# USB0_VBP2APB_WRAP_CONTROLLER_VBP_CORE_ADDR_MAP register map
Vendor: Texas Instruments
Registers are 32-bit, access per field, reset 0x0 unless marked. A register's access mark holds for its fields unless they carry their own. Offsets are as the file gives them; [hi:lo] are bit positions; {n}, {i} and the like mark numbered series.

## USB0_VBP2APB_WRAP_CONTROLLER_VBP_CORE_ADDR_MAP (part 3 of 9)
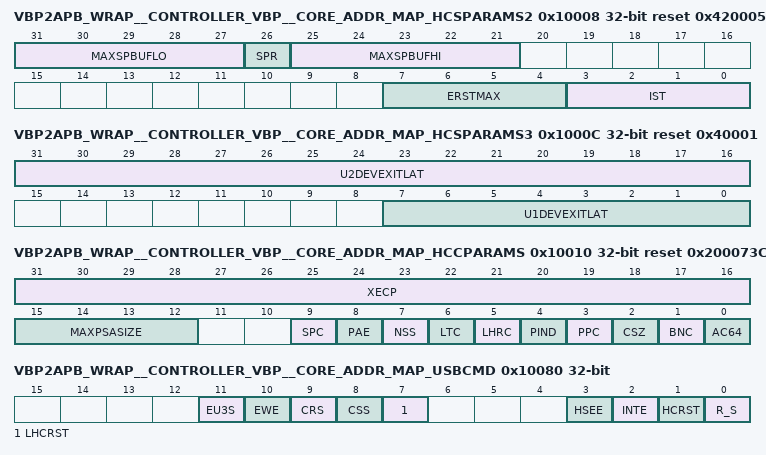
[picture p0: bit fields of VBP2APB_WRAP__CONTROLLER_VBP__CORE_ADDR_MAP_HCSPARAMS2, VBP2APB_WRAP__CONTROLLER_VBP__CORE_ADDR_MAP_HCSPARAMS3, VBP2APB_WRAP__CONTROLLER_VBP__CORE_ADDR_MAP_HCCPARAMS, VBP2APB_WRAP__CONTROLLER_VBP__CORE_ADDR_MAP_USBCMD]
0x10008 VBP2APB_WRAP__CONTROLLER_VBP__CORE_ADDR_MAP_HCSPARAMS2 ro reset 0x4200054 — Structural Parameters 2 (HCSPARAMS 2). This register defines additional xHC structural parameters.
  [31:27] MAXSPBUFLO — Max Scratchpad Buffers [Max Scratchpad Bufs Lo]. Default = implementation dependent. Valid values for Max Scratchpad Buffers [Hi and Lo] are 0-1023. This field indicates the low order 5 bits of the number of Scratchpad Buffers system software shall reserve for the xHC. Refer to section 4.20 of xHCI specification for more information.
  [26] SPR — Scratchpad Restore [SPR]. Default = implementation dependent. If Max Scratchpad Buffers is > 0 then this flag indicates whether the xHC uses the Scratchpad Buffers for saving state when executing Save and Restore State operations. If Max Scratchpad Buffers is = 0 then this flag shall be 0. Refer to section 4.23.2 of xHCI specification for more information. A value of '1' indicates that the xHC requires the integrity of the Scratchpad Buffer space to be maintained across power events. A value of '0' indicates that the Scratchpad Buffer space may be freed and reallocated between power events.
  [25:21] MAXSPBUFHI — Max Scratchpad Buffers [Max Scratchpad Bufs Hi]. Default = implementation dependent. This field indicates the high order 5 bits of the number of Scratchpad Buffers system software shall reserve for the xHC. Refer to section 4.20 of xHCI specification for more information.
  [7:4] ERSTMAX — Event Ring Segment Table Max [ERST Max]. Default = implementation dependent. Valid values are 0-15. This field determines the maximum value supported the Event Ring Segment Table Base Size registers [5.5.2.3.1], where: The maximum number of Event Ring Segment Table entries = 2 ^[ERSTMax], e.g. if the ERST Max = 7, then the xHC Event Ring Segment Table[s] supports up to 128 entries, 15 then 32K entries, etc.
  [3:0] IST — Isochronous Scheduling Threshold [IST]. Default = implementation dependent. The value in this field indicates to system software the minimum distance [in time] that it is required to stay ahead of the host controller while adding TRBs, in order to have the host controller process them at the correct time. The value shall be specified in terms of number of frames/microframes. If bit [3] of IST is cleared to '0', software can add a TRB no later than IST[2:0] Microframes before that TRB is scheduled to be executed. If bit [3] of IST is set to '1', software can add a TRB no later than IST[2:0] Frames before that TRB is scheduled to be executed. Refer to Section 4.14.2 of xHCI specification for details on how software uses this information for scheduling isochronous transfers.
0x1000C VBP2APB_WRAP__CONTROLLER_VBP__CORE_ADDR_MAP_HCSPARAMS3 ro reset 0x40001 — Structural Parameters 3 (HCSPARAMS3). This register defines link exit latency related structural parameters.
  [31:16] U2DEVEXITLAT — U2 Device Exit Latency. Worst case latency to transition from U2 to U0. Applies to all root hub ports. The following are permissible values: 0000h Zero, 0001h Less than 1 s., 0002h Less than 2 s., ... 07FFh Less than 2047 s., 0800-FFFFh Reserved
  [7:0] U1DEVEXITLAT — U1 Device Exit Latency. Worst case latency to transition a root hub Port Link State [PLS] from U1 to U0. Applies to all root hub ports. The following are permissible values: 00h Zero, 01h Less than 1 s., 02h Less than 2 s., ... 0Ah Less than 10 s., 0B-FFh Reserved.
0x10010 VBP2APB_WRAP__CONTROLLER_VBP__CORE_ADDR_MAP_HCCPARAMS ro reset 0x200073C9 — Capability Parameters (HCCPARAMS). This register defines optional capabilities supported by the xHCI. The default values for all fields in this register are implementation dependent.
  [31:16] XECP — xHCI Extended Capabilities Pointer [xECP]. This field indicates the existence of a capabilities list. The value of this field indicates a relative offset, in 32-bit words, from Base to the beginning of the first extended capability. For example, using the offset of Base is 1000h and the xECP value of 0068h, we can calculate the following effective address of the first extended capability: 1000h + [0068h shifted left 2] -> 1000h + 01A0h -> 11A0h
  [15:12] MAXPSASIZE — Maximum Primary Stream Array Size [MaxPSASize]. This fields identifies the maximum size Primary Stream Array that the xHC supports. The Primary Stream Array size = 2^[MaxPSASize+1]. Valid MaxPSASize values are 0 to 15, where 0 indicates that Streams are not supported.
  [9] SPC — Stopped - Short Packet Capability [SPC]. This flag indicates that the host controller implementation is capable of generating a Stopped - Short Packet Completion Code. Refer to section 4.6.9 of xHCI specification for more information.
  [8] PAE — Parse All Event Data [PAE]. This flag indicates whether the host controller implementation Parses all Event Data TRBs while advancing to the next TD after a Short Packet, or it skips all but the first Event Data TRB. A '1' in this bit indicates that all Event Data TRBs are parsed. A '0' in this bit indicates that only the first Event Data TRB is parsed [refer to section 4.10.1.1 of xHCI specification].
  [7] NSS — No Secondary SID Support [NSS]. This flag indicates whether the host controller implementation supports Secondary Stream IDs. A '1'in this bit indicates that Secondary Stream ID decoding is not supported. A '0' in this bit indicates that Secondary Stream ID decoding is supported. [refer to Sections 4.12.2 and 6.2.3 of xHCI specification].
  [6] LTC — Latency Tolerance Messaging Capability [LTC]. This flag indicates whether the host controller implementation supports Latency Tolerance Messaging [LTM]. A '1' in this bit indicates that LTM is supported. A 0 in this bit indicates that LTM is not supported. Refer to section 4.13.1 of xHCI specification for more information on LTM.
  [5] LHRC — Light HC Reset Capability [LHRC]. This flag indicates whether the host controller implementation supports a Light Host Controller Reset. A '1' in this bit indicates that Light Host Controller Reset is supported. A '0' in this bit indicates that Light Host Controller Reset is not supported. The value of this flag affects the functionality of the Light Host Controller Reset [LHCRST] flag in the USBCMD register [refer to Section 5.4.1 of xHCI specification].
  [4] PIND — Port Indicators [PIND]. This bit indicates whether the xHC root hub ports support port indicator control. When this bit is a '1', the port status and control registers include a read/writeable field for controlling the state of the port indicator. Refer to Section 5.4.8 of xHCI specification for definition of the Port Indicator Control field [PIC field of PORTSC register].
  [3] PPC — Port Power Control [PPC]. This flag indicates whether the host controller implementation includes port power control. A '1' in this bit indicates the ports have port power switches. A '0' in this bit indicates the port do not have port power switches. The value of this flag affects the functionality of the PP flag in each port status and control register [refer to Section 5.4.8 of xHCI specification]. When DEBUG_CTRL_REG capability is used [CDNS_RM_CBIT_DEBUG_CTRL_REG is not defined] then this bit is treated as RW. Its value can be changed only by writes to bit 8 of DEBUG_CTRL_REG [port_pwr_ctrl_toggle]. Direct writes to this bit are not possible.
  [2] CSZ — Context Size [CSZ]. If this bit is set to '1', then the xHC uses 64 byte Context data structures. If this bit is cleared to 0, then the xHC uses 32 byte Context data structures. Note: This flag does not apply to Stream Contexts.
  [1] BNC — BW Negotiation Capability [BNC]. This flag identifies whether the xHC has implemented the Bandwidth Negotiation. Values for this flag have the following interpretation: '0': BW Negotiation not implemented '1': BW Negotiation implemented Refer to section 4.16 of xHCI specification for more information on Bandwidth Negotiation.
  [0] AC64 — 64-bit Addressing Capability [AC64]. This flag documents the addressing range capability of this implementation. The value of this flag determines whether the xHC has implemented the high order 32 bits of 64 bit register and data structure pointer fields. Values for this flag have the following interpretation: '0': 32-bit address memory pointers implemented, '1': 64-bit address memory pointers implemented. If 32-bit address memory pointers are implemented, the xHC shall ignore the high order 32 bits of 64 bit data structure pointer fields, and system software shall ignore the high order 32 bits of 64 bit xHC registers.
0x10014 VBP2APB_WRAP__CONTROLLER_VBP__CORE_ADDR_MAP_DBOFF ro reset 0x3000 — This register defines the offset of the Doorbell Array base address from the Base.
  [31:2] DAO — Doorbell Array Offset, RO. Default = implementation dependent. This field defines the offset in Dwords of the Doorbell Array base address from the Base [i.e. the base address of the xHCI Capability register address space].
0x10018 VBP2APB_WRAP__CONTROLLER_VBP__CORE_ADDR_MAP_RTSOFF ro reset 0x2000 — This register defines the offset of the xHCI Runtime Registers from the Base.
  [31:5] RRSO — Runtime Register Space Offset, RO. Default = implementation dependent. This field defines the 32-byte offset of the xHCI Runtime Registers from the Base. i.e. Runtime Register Base Address = Base + Runtime Register Set Offset.
0x1001C VBP2APB_WRAP__CONTROLLER_VBP__CORE_ADDR_MAP_HCCPARAMS2 ro reset 0x8 — Capability Parameters 2 (HCCPARAMS2). This register defines optional capabilities supported by the xHCI. The default values for all fields in this register are implementation dependent.
  [3] CTC — This bit indicates whether the xHC USB3 Root Hub ports support the Compliance Transition Enabled [CTE] flag. When this bit is 1 USB3 Root Hub port state machine transitions to the Compliance substate shall be explicitly enabled software. When this bit is 0. USB3 Root Hub port state machine transitions to the Compliance substate are automatically enabled.
0x10020 VBP2APB_WRAP__CONTROLLER_VBP__CORE_ADDR_MAP_RSVD_CR ro — Reserved: Reserved for future RO implementations. Registers or memory that shall be treated as read-only by system software. Rsvd registers shall return zero when read. Software shall ignore the value read from these bits.
0x10080 VBP2APB_WRAP__CONTROLLER_VBP__CORE_ADDR_MAP_USBCMD — USB Command Register (USBCMD). The Command Register indicates the command to be executed by the serial bus host controller. Writing to the register causes a command to be executed.
  [11] EU3S rw — Enable U3 MFINDEX Stop [EU3S], RW. Default = '0'. When set to '1', the xHC may stop the MFINDEX counting action if all Root Hub ports are in the U3, Disconnected, Disabled, or Powered-off state. When cleared to '0' the xHC may stop the MFINDEX counting action if all Root Hub ports are in the Disconnected, Disabled, Training, or Powered-off state. Refer to section 4.14.2 of xHCI specification for more information.
  [10] EWE rw — Enable Wrap Event [EWE], RW. Default = '0'. When set to '1', the xHC shall generate a MFINDEX Wrap Event every time the MFINDEX register transitions from 03FFFh to 0. When cleared to '0' no MFINDEX Wrap Events are generated. Refer to section 4.14.2 of xHCI specification for more information. When this register is exposed by a Virtual Function [VF], the generation of MFINDEX Wrap Events to VFs shall be emulated by the VMM.
  [9] CRS rw — Controller Restore State [CRS], RW. Default = '0'. When set to '1', and HCHalted [HCH] = '1', then the xHC shall perform a Restore State operation and restore its internal state. When set to '1' and Run/Stop [R/S] = '1' or HCHalted [HCH] = '0', or when cleared to '0', no Restore State operation shall be performed. This flag always returns '0' when read. Refer to the Restore State Status [RSS] flag in the USBSTS register for information on Restore State completion. Refer to section 4.23.2 of xHCI specification for more information. Note that undefined behavior may occur if a Restore State operation is initiated while Save State Status [SSS] = '1'. When this register is exposed by a Virtual Function [VF], this bit only controls restoring the state of the xHC instance presented by the selected VF. Refer to section 8 of xHCI specification for more information.
  [8] CSS rw — Controller Save State [CSS], RW. Default = '0'. When written by software with '1' and HCHalted [HCH] = '1', then the xHC shall save any internal state that may be restored by a subsequent Restore State operation. When written by software with '1' and HCHalted [HCH] = '0', or written with '0', no Save State operation shall be performed. This flag always returns '0' when read. Refer to the Save State Status [SSS] flag in the USBSTS register for information on Save State completion. Refer to section 4.23.2 of xHCI specification for more information on xHC Save/Restore operation. Note that undefined behavior may occur if a Save State operation is initiated while Restore State Status [RSS] ='1'. When this register is exposed by a Virtual Function [VF], this bit only controls saving the state of the xHC instance presented by the selected VF. Refer to section 8 of xHCI specifications for more information.
  [7] LHCRST ro — Light Host Controller Reset [LHCRST], RO or RW. Optional normative. Default = '0'. If the Light HC Reset Capability [LHRC] bit in the HCCPARAMS register is '1', then this flag allows the driver to reset the xHC without affecting the state of the ports. A system software read of this bit as '0' indicates the Light Host Controller Reset has completed and it is safe for software to re-initialize the xHC. A software read of this bit as a '1' indicates that the Light Host Controller Reset has not yet completed. If not implemented, a read of this flag shall always return a '0'. All registers in the Aux Power well shall maintain the values that had been asserted prior to the Light Host Controller Reset. Refer to section 4.23.1 of xHCI specification for more information. When this register is exposed by a Virtual Function [VF], this bit only generates a Light Reset to the xHC instance presented by the selected VF, e.g. Disable the VFs device slots and set the associated VF Run bit to Stopped. Refer to section 8 of xHCI specification for more information.
  [3] HSEE rw — Host System Error Enable [HSEE], RW. Default = '0'. When this bit is a '1', and the HSE bit in the USBSTS register is a '1', the xHC shall assert out-of-band error signaling to the host. The signaling is acknowledged by software clearing the HSE bit. Refer to section 4.10.2.6 of xHCI specification for more information. When this register is exposed by a Virtual Function [VF], the effect of the assertion of this bit on the Physical Function [PF0] is determined by the VMM. Refer to section 8 of xHCI specification for more information.
  [2] INTE rw — Interrupter Enable [INTE], RW. Default = '0'. This bit provides system software with a means of enabling or disabling the host system interrupts generated by Interrupters. When this bit is a '1', then Interrupter host system interrupt generation is allowed, e.g. the xHC shall issue an interrupt at the next interrupt threshold if the host system interrupt mechanism [e.g. MSI, MSIX, etc.] is enabled. The interrupt is acknowledged by a host system interrupt specific mechanism. When this register is exposed by a Virtual Function [VF], this bit only enables the set of Interrupters assigned to the selected VF. Refer to section 7.7.2 of xHCI specification for more information.
  [1] HCRST rw — Host Controller Reset [HCRST], RW. Default = '0'. This control bit is used by software to reset the host controller. The effects of this bit on the xHC and the Root Hub registers are similar to a Chip Hardware Reset. When software writes a '1' to this bit, the Host Controller resets its internal pipelines, timers, counters, state machines, etc. to their initial value. Any transaction currently in progress on the USB is immediately terminated. A USB reset shall not be driven on USB2 downstream ports, however a Hot or Warm Reset shall be initiated on USB3 Root Hub downstream ports. PCI Configuration registers are not affected by this reset. All operational registers, including port registers and port state machines are set to their initial values. Software shall reinitialize the host controller as described in Section 4.1 of xHCI specification in order to return the host controller to an operational state. This bit is cleared to '0' by the Host Controller when the reset process is complete. Software cannot terminate the reset process early by writing a '0' to this bit and shall not write any xHC Operational or Runtime registers until while HCRST is '1'. Note, the completion of the xHC reset process is not gated by the Root Hub port reset process. Software shall not set this bit to '1' when the HCHalted [HCH] bit in the USBSTS register is a '0'. Attempting to reset an actively running host controller may result in undefined behavior. When this register is exposed by a Virtual Function [VF], this bit only resets the xHC instance presented by the selected VF. Refer to section 8 of xHCI specification for more information.
  [0] R_S rw — Run/Stop [R/S], RW. Default = '0'. '1' = Run. '0' = Stop. When set to a '1', the xHC proceeds with execution of the schedule. The xHC continues execution as long as this bit is set to a '1'. When this bit is cleared to '0', the xHC completes any current or queued commands or TDs, and any USB transactions associated with them, then halts. Refer to section 5.4.1.1 of xHCI specification for more information on how R/S shall be managed. The xHC shall halt within 16 ms after software clears the Run/Stop bit if the above conditions have been met. The HCHalted [HCH] bit in the USBSTS register indicates when the xHC has finished its pending pipelined transactions and has entered the stopped state. Software shall not write a '1' to this flag unless the xHC is in the Halted state [i.e. HCH in the USBSTS register is '1']. Doing so may yield undefined results. Writing a '0' to this flag when the xHC is in the Running state [i.e. HCH = '0'] and any Event Rings are in the Event Ring Full state [refer to section 4.9.4 of xHCI specification] may result in lost events. When this register is exposed by a Virtual Function [VF], this bit only controls the run state of the xHC instance presented by the selected VF. Refer to section 8 of xHCI specification for more information.
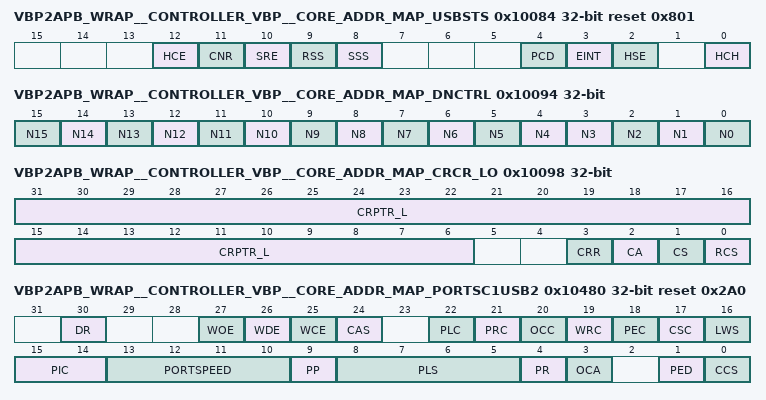
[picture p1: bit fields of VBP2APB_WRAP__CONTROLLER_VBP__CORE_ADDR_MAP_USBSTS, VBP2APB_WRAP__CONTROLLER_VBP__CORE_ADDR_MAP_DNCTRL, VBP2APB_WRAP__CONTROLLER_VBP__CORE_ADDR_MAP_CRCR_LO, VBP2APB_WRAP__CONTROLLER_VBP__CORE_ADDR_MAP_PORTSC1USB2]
0x10084 VBP2APB_WRAP__CONTROLLER_VBP__CORE_ADDR_MAP_USBSTS access not given reset 0x801 — USB Status Register (USBSTS). This register indicates pending interrupts and various states of the Host Controller. The status resulting from a transaction on the serial bus is not indicated in this register. Software sets a bit to '0' in this register by writing a '1' to it (RW1C). Refer to Section 4.17 of xHCI specification for additional information concerning USB interrupt conditions.
  [12] HCE ro — Host Controller Error [HCE], RO. Default = '0'. '0' = No internal xHC error conditions exist and '1' = Internal xHC error condition. This flag shall be set to indicate that an internal error condition has been detected which requires software to reset and reinitialize the xHC. Refer to section 4.24.1 of xHCI specification for more information.
  [11] CNR ro — Controller Not Ready [CNR], RO. Default = '1'. '0' = Ready and '1' = Not Ready. When this bit is '1', software shall not read or write any register of the xHC, other than those explicitly listed in the Design Specification section titled Register Accessibility. This flag is set by the xHC after a Chip Hardware Reset and cleared when the xHC is ready to begin accepting register reads or writes to all registers. This flag shall remain cleared ['0'] until the next Chip Hardware Reset.
  [10] SRE — Save/Restore Error [SRE], RW1C. Default = '0'. If an error occurs during a Save or Restore operation this bit shall be set to '1'. This bit shall be cleared to '0' when a Save or Restore operation is initiated or when written with '1'. Refer to section 4.23.2 of xHCI specification for more information. When this register is exposed by a Virtual Function [VF], the VMM determines the state of this bit as a function of the Save/Restore completion status for the selected VF. Refer to section 8 of xHCI specification for more information. (access R/W1TC)
  [9] RSS ro — Restore State Status [RSS], RO. Default = '0'. When the Controller Restore State [CRS] flag in the USBCMD register is written with '1' this bit shall be set to '1' and remain '1' while the xHC restores its internal state. When the Restore State operation is complete, this bit shall be cleared to '0'. Refer to section 4.23.2 of xHCI specification for more information. When this register is exposed by a Virtual Function [VF], the VMM determines the state of this bit as a function of the restoring the state for the selected VF. Refer to section 8 of xHCI specification for more information.
  [8] SSS ro — Save State Status [SSS], RO. Default = '0'. When the Controller Save State [CSS] flag in the USBCMD register is written with '1' this bit shall be set to '1' and remain '1' while the xHC saves its internal state. When the Save State operation is complete, this bit shall be cleared to '0'. Refer to section 4.23.2 of xHCI specification for more information. When this register is exposed by a Virtual Function [VF], the VMM determines the state of this bit as a function of the saving the state for the selected VF. Refer to section 8 of xHCI specification for more information.
  [4] PCD — Port Change Detect [PCD], RW1C. Default = '0'. The xHC sets this bit to a '1' when any port has a change bit transition from a '0' to a '1'. This bit is allowed to be maintained in the Aux Power well. Alternatively, it is also acceptable that on a D3 to D0 transition of the xHC, this bit is loaded with the OR of all of the PORTSC change bits. Refer to section 4.19.3 of xHCI specification. This bit provides system software an efficient means of determining if there has been Root Hub port activity. Refer to section 4.15.2.3 of xHCI specification for more information. When this register is exposed by a Virtual Function [VF], the VMM determines the state of this bit as a function of the Root Hub Ports associated with the Device Slots assigned to the selected VF. Refer to section 8 of xHCI specification for more information. (access R/W1TC)
  [3] EINT — Event Interrupt [EINT], RW1C. Default = '0'. The xHC sets this bit to '1' when the Interrupt Pending [IP] bit of any Interrupter transitions from '0' to '1'. Refer to section 7.1.2 of xHCI specification for use. Software that uses EINT shall clear it prior to clearing any IP flags. A race condition may occur if software clears the IP flags then clears the EINT flag, and between the operations another IP '0' to '1' transition occurs. In this case the new IP transition shall be lost. When this register is exposed by a Virtual Function [VF], this bit is the logical 'OR' of the IP bits for the Interrupters assigned to the selected VF. And it shall be cleared to '0' when all associated interrupter IP bits are cleared, i.e. all the VFs Interrupter Event Ring[s] are empty. Refer to section 8 of xHCI specification for more information (access R/W1TC)
  [2] HSE — Host System Error [HSE], RW1C. Default = '0'. The xHC sets this bit to '1' when a serious error is detected, either internal to the xHC or during a host system access involving the xHC module. [In a PCI system, conditions that set this bit to 1 include PCI Parity error, PCI Master Abort, and PCI Target Abort.] When this error occurs, the xHC clears the Run/Stop [R/S] bit in the USBCMD register to prevent further execution of the scheduled TDs. If the HSEE bit in the USBCMD register is a '1', the xHC shall also assert out-of-band error signaling to the host. Refer to section 4.10.2.6 of xHCI specification for more information. When this register is exposed by a Virtual Function [VF], the assertion of this bit affects all VFs and reflects the Host System Error state of the Physical Function [PF0]. Refer to section 8 of xHCI specification for more information. (access R/W1TC)
  [0] HCH ro — HCHalted [HCH], RO. Default = '1'. This bit is a '0' whenever the Run/Stop [R/S] bit is a '1'. The xHC sets this bit to '1' after it has stopped executing as a result of the Run/Stop [R/S] bit being cleared to '0', either by software or by the xHC hardware [e.g. internal error]. If this bit is '1', then SOFs, microSOFs, or Isochronous Timestamp Packets [ITP] shall not be generated by the xHC, and any received Transaction Packet shall be dropped. When this register is exposed by a Virtual Function [VF], this bit only reflects the Halted state of the xHC instance presented by the selected VF. Refer to section 8 of xHCI specification for more information.
0x10088 VBP2APB_WRAP__CONTROLLER_VBP__CORE_ADDR_MAP_PAGESIZE ro reset 0x1 — Page Size Register (PAGESIZE).
  [15:0] PAGESIZE — Page Size, RO. Default = Implementation defined. This field defines the page size supported by the xHC implementation. This xHC supports a page size of 2^[n+12] if bit n is Set. For example, if bit 0 is Set, the xHC supports 4k byte page sizes. For a Virtual Function, this register reflects the page size selected in the System Page Size field of the SR-IOV Extended Capability structure. For the Physical Function 0, this register reflects the implementation dependent default xHC page size. Various xHC resources reference PAGESIZE to describe their minimum alignment requirements. The maximum possible page size is 128M.
0x1008C VBP2APB_WRAP__CONTROLLER_VBP__CORE_ADDR_MAP_RSVDZ8C ro — Reserved and Zero: Reserved for future RW1C implementations. Software shall use zero for writes to these bits.
0x10090 VBP2APB_WRAP__CONTROLLER_VBP__CORE_ADDR_MAP_RSVDZ90 ro — Reserved and Zero: Reserved for future RW1C implementations. Software shall use zero for writes to these bits.
0x10094 VBP2APB_WRAP__CONTROLLER_VBP__CORE_ADDR_MAP_DNCTRL — Device Notification Control Register (DNCTRL). This register is used by software to enable or disable the reporting of the reception of specific USB Device Notification Transaction Packets. A Notification Enable (Nx, where x = 0 to 15) flag is defined for each of the 16 possible device notification types. If a flag is set for a specific notification type, a Device Notification Event shall be generated when the respective notification packet is received. After reset all notifications are disabled. Refer to section 6.4.2.7 of xHCI specification. This register shall be written as a Dword. Byte writes produce undefined results. When a Notification Enable bit is set, a Device Notification Event shall be generated when a Device Notification Transaction Packet is received with the matching value in the Notification Type field. For example, setting N1 to '1' enables Device Notification Event generation if a Device Notification TP is received with its Notification Type field set to '1' (FUNCTION_WAKE), etc. Note: Of the currently defined USB3 Device Notification Types, only the FUNCTION_WAKE type should not be handled automatically by the xHC. Only under debug conditions would software write the DNCTRL register with a value other than 0002h. Refer to section 8.5.6 in the USB3 specification for more information on Notification Types. If new Device Notification Types are defined, software may receive them by setting the respective Notification Enable bit.
  [n] N{n} rw (n=4..15) — Notification Enable flag {n}
  [3] N3 rw — Notification Enable flag 3. BUS_INTERVAL_ADJUSTMENT_MESSAGE.
  [2] N2 rw — Notification Enable flag 2. LATENCY_TOLERANCE_MESSAGE.
  [1] N1 rw — Notification Enable flag 1
  [0] N0 rw — Notification Enable flag 0
0x10098 VBP2APB_WRAP__CONTROLLER_VBP__CORE_ADDR_MAP_CRCR_LO access not given — Command Ring Control Register Low (CRCR_L). The Command Ring Control Register provides Command Ring control and status capabilities, and identifies the address and Cycle bit state of the Command Ring Dequeue Pointer.
  [31:6] CRPTR_L rw — Command Ring Pointer Low, RW. Default = 0. This field defines low order bits of the initial value of the 64-bit Command Ring Dequeue Pointer. Writes to this field are ignored when Command Ring Running [CRR] = '1'. If the CRCR is written while the Command Ring is stopped [CCR = '0'], the value of this field shall be used to fetch the first Command TRB the next time the Host Controller Doorbell register is written with the DB Reason field set to Host Controller Command. If the CRCR is not written while the Command Ring is stopped [CCR = '0'] then the Command Ring shall begin fetching Command TRBs at the current value of the internal xHC Command Ring Dequeue Pointer. Reading this field always returns zero.
  [3] CRR ro — Command Ring Running [CRR], RO. Default = '0'. This flag is set to '1' if the Run/Stop [R/S] bit is '1' and the Host Controller Doorbell register is written with the DB Reason field set to Host Controller Command. It is cleared to '0' when the Command Ring is stopped after writing a '1' to the Command Stop [CS] or Command Abort [CA] flags, or if the R/S bit is cleared to '0'.
  [2] CA — Command Abort [CA], RW1S. Default = '0'. Writing a '1' to this bit shall immediately terminate the currently executing command, stop the Command Ring, and generate a Command Completion Event with the Completion Code set to Command Ring Stopped. Refer to section 4.6.1.2 of xHCI specification for more information on aborting a command. The next write to the Host Controller Doorbell with DB Reason field set to Host Controller Command shall restart the Command Ring operation. Writes to this flag are ignored by the xHC if Command Ring Running [CRR] = '0'. Reading this bit always returns '0'. (access R/W1TS)
  [1] CS — Command Stop [CS], RW1S. Default = '0'. Writing a '1' to this bit shall stop the operation of the Command Ring after the completion of the currently executing command, and generate a Command Completion Event with the Completion Code set to Command Ring Stopped and the Command TRB Pointer set to the current value of the Command Ring Dequeue Pointer. Refer to section 4.6.1.1 of xHCI specification for more information on stopping a command. The next write to the Host Controller Doorbell with DB Reason field set to Host Controller Command shall restart the Command Ring operation. Writes to this flag are ignored by the xHC if Command Ring Running [CRR] = '0'. Reading this bit shall always return '0'. (access R/W1TS)
  [0] RCS rw — Ring Cycle State [RCS], RW. This bit identifies the value of the xHC Consumer Cycle State [CCS] flag for the TRB referenced by the Command Ring Pointer. Refer to section 4.9.3 of xHCI specification for more information. Writes to this flag are ignored if Command Ring Running [CRR] is '1'. If the CRCR is written while the Command Ring is stopped [CRR = '0'], then the value of this flag shall be used to fetch the first Command TRB the next time the Host Controller Doorbell register is written with the DB Reason field set to Host Controller Command. If the CRCR is not written while the Command Ring is stopped [CRR = '0'], then the Command Ring shall begin fetching Command TRBs using the current value of the internal Command Ring CCS flag. Reading this flag always returns '0'.
0x1009C VBP2APB_WRAP__CONTROLLER_VBP__CORE_ADDR_MAP_CRCR_HI rw — Command Ring Control Register High (CRCR_HI). The Command Ring Control Register provides high order bits of the Command Ring Dequeue Pointer.
  [31:0] CRPTR_H — Command Ring Pointer High, RW. Default = 0. This field defines high order bits of the initial value of the 64-bit Command Ring Dequeue Pointer. Writes to this field are ignored when Command Ring Running [CRR] = '1'. If the CRCR is written while the Command Ring is stopped [CCR = '0'], the value of this field shall be used to fetch the first Command TRB the next time the Host Controller Doorbell register is written with the DB Reason field set to Host Controller Command. If the CRCR is not written while the Command Ring is stopped [CCR = '0'] then the Command Ring shall begin fetching Command TRBs at the current value of the internal xHC Command Ring Dequeue Pointer. Reading this field always returns zero.
0x100A0 VBP2APB_WRAP__CONTROLLER_VBP__CORE_ADDR_MAP_RSVDZA0 ro — Reserved and Zero: Reserved for future RW1C implementations. Software shall use zero for writes to these bits.
0x100A4 VBP2APB_WRAP__CONTROLLER_VBP__CORE_ADDR_MAP_RSVDZA4 ro — Reserved and Zero: Reserved for future RW1C implementations. Software shall use zero for writes to these bits.
0x100A8 VBP2APB_WRAP__CONTROLLER_VBP__CORE_ADDR_MAP_RSVDZA8 ro — Reserved and Zero: Reserved for future RW1C implementations. Software shall use zero for writes to these bits.
0x100AC VBP2APB_WRAP__CONTROLLER_VBP__CORE_ADDR_MAP_RSVDZAC ro — Reserved and Zero: Reserved for future RW1C implementations. Software shall use zero for writes to these bits.
0x100B0 VBP2APB_WRAP__CONTROLLER_VBP__CORE_ADDR_MAP_DCBAAP_LO — Device Context Base Address Array Pointer Register (DCBAAP_LO). The Device Context Base Address Array Pointer Register identifies the base address of the Device Context Base Address Array. The memory structure referenced by this physical memory pointer is assumed to be physically contiguous and 64-byte aligned.
  [31:6] DCBAAPTR_L rw — Device Context Base Address Array Pointer, RW. Default = 0. This field defines low order bits of the 64-bit base address of the Device Context Pointer Array. A table of address pointers that reference Device Context structures for the devices attached to the host.
0x100B4 VBP2APB_WRAP__CONTROLLER_VBP__CORE_ADDR_MAP_DCBAAP_HI rw — Device Context Base Address Array Pointer Register (DCBAAP_HI). The Device Context Base Address Array Pointer Register identifies the base address of the Device Context Base Address Array. The memory structure referenced by this physical memory pointer is assumed to be physically contiguous and 64-byte aligned.
  [31:0] DCBAAPTR_H — Device Context Base Address Array Pointer, RW. Default = 0. This field defines high order bits of the 64-bit base address of the Device Context Pointer Array. A table of address pointers that reference Device Context structures for the devices attached to the host.
0x100B8 VBP2APB_WRAP__CONTROLLER_VBP__CORE_ADDR_MAP_CONFIG — Configure Register (CONFIG). This register defines runtime xHC configuration parameters.
  [7:0] MAXSLOTSEN rw — Max Device Slots Enabled [MaxSlotsEn], RW. Default = 0. This field specifies the maximum number of enabled Device Slots. Valid values are in the range of 0 to MaxSlots. Enabled Devices Slots are allocated contiguously. e.g. A value of 16 specifies that Device Slots 1 to 16 are active. A value of 0 disables all Device Slots. A disabled Device Slot shall not respond to Doorbell Register references. This field shall not be modified by software if the xHC is running [Run/Stop [R/S] = 1].
0x100BC VBP2APB_WRAP__CONTROLLER_VBP__CORE_ADDR_MAP_RSVDZBC ro — Reserved and Zero: Reserved for future RW1C implementations. Software shall use zero for writes to these bits.
0x100C0 VBP2APB_WRAP__CONTROLLER_VBP__CORE_ADDR_MAP_RSVDZ_OP ro — Reserved and Zero: Reserved for future RW1C implementations. Software shall use zero for writes to these bits.
0x10480 VBP2APB_WRAP__CONTROLLER_VBP__CORE_ADDR_MAP_PORTSC1USB2 access not given reset 0x2A0 — Port Status and Control Register for USB2 protocol port. This register may be read from or written to at any time, including whilst the CNR field in the USBSTS register is high.
  [30] DR ro — Device Removable [DR], RO. This flag indicates if this port has a removable device attached. '0' = Device is removable. '1' = Device is non-removable.
  [27] WOE rw — Wake on Over-current Enable [WOE], RWS. Default = '0'. Writing this bit to a '1' enables the port to be sensitive to over-current conditions as system wake-up events. Refer to section 4.15 of xHCI specification for operational model.
  [26] WDE rw — Wake on Disconnect Enable [WDE], RWS. Default = '0'. Writing this bit to a '1' enables the port to be sensitive to device disconnects as system wake-up events. Refer to section 4.15 of xHCI specification for operational model.
  [25] WCE rw — Wake on Connect Enable [WCE], RWS. Default = '0'. Writing this bit to a '1' enables the port to be sensitive to device connects as system wake-up events. Refer to section 4.15 of xHCI specification for operational model.
  [24] CAS ro — Cold Attach Status [CAS], RO. Default = '0'. '1' = Far-end Receiver Terminations were detected in the Disconnected state and the Root Hub Port State Machine was unable to advance to the Enabled state. Refer to sections 4.19.8 of xHCI specification for more details on the Cold Attach Status [CAS] assertion conditions. Software shall clear this bit by writing a '1' to WPR or the xHC shall clear this bit if CCS transitions to '1'. This flag is '0' for USB2 protocol ports.
  [22] PLC — Port Link State Change [PLC], RW1CS. Default = '0'. This flag is set to '1' due to the following PLS transitions: U3 -> Resume [Wakeup signaling from a device], Resume -> Recovery -> U0 [Device Resume complete [USB3 protocol ports only]], Resume -> U0 [Device Resume complete [USB2 protocol ports only]], U3 -> Recovery -> U0 [Software Resume complete [USB3 protocol ports only]], U3 -> U0 [Software Resume complete [USB2 protocol ports only]], U2 -> U0 [L1 Resume complete [USB2 protocol ports only]], U0 -> U0 [L1 Entry Reject [USB2 protocol ports only]], Any state -> Inactive [Error [USB3 protocol ports only]]. Note that this flag shall not be set if the PLS transition was due to software setting PP to 0. Refer to section 4.23.5 of xHCI specification for more information. '0' = No change. '1' = Link Status Changed. Software shall clear this bit by writing a '1' to it. Refer to PLC Condition: references in section 4.19.1 for the specific port state transitions that set this flag. Refer to section 4.19.2 of xHCI specification for more information on change bit usage. (access R/W1TC)
  [21] PRC — Port Reset Change [PRC], RW1CS. Default = '0'. This flag is set to '1' due to a '1' to '0' transition of Port Reset [PR], e.g. when any reset processing [Warm or Hot] on this port is complete. Note that this flag shall not be set to '1' if the reset processing was forced to terminate due to software clearing PP or PED to '0'. '0' = No change. '1' = Reset complete. Software shall clear this bit by writing a '1' to it. Refer to section 4.19.5 of xHCI specification. Refer to section 4.19.2 of xHCI specification for more information on change bit usage. (access R/W1TC)
  [20] OCC — Over-current Change [OCC], RW1CS. Default = '0'. This bit shall be set to a '1' when there is a '0' to '1' or '1' to '0' transition of Over-current Active [OCA]. Software shall clear this bit by writing a '1' to it. Refer to section 4.19.2 of xHCI specification for more information on change bit usage. (access R/W1TC)
  [19] WRC — Warm Port Reset Change [WRC], RW1CS/RsvdZ. Default = '0'. This bit is set when Warm Reset processing on this port completes. '0' = No change. '1' = Warm Reset complete. Note that this flag shall not be set to '1' if the Warm Reset processing was forced to terminate due to software clearing PP or PED to '0'. Software shall clear this bit by writing a '1' to it. Refer to section 4.19.5.1 of xHCI specification. Refer to section 4.19.2 of xHCI specification for more information on change bit usage. This bit only applies to USB3 protocol ports. For USB2 protocol ports it shall be RsvdZ. (access R/W1TC)
  [18] PEC — Port Enabled/Disabled Change [PEC], RW1CS. Default = '0'. '1' = change in PED. '0' = No change. Note that this flag shall not be set if the PED transition was due to software setting PP to '0'. Software shall clear this bit by writing a '1' to it. Refer to section 4.19.2 of xHCI specification for more information on change bit usage. This bit shall be set to '1' only when the port is disabled due to the appropriate conditions existing at the EOF2 point [refer to section 11.8.1 of the USB2 Specification for the definition of a Port Error]. (access R/W1TC)
  [17] CSC — Connect Status Change [CSC], RW1CS. Default = '0'. '1' = Change in CCS. '0' = No change. This flag indicates a change has occurred in the ports Current Connect Status [CCS] or Cold Attach Status [CAS] bits. Note that this flag shall not be set if the CCS transition was due to software setting PP to '0', or the CAS transition was due to software setting WPR to '1'. The xHC sets this bit to '1' for all changes to the port device connect status, even if system software has not cleared an existing Connect Status Change. For example, the insertion status changes twice before system software has cleared the changed condition, root hub hardware will be setting an already-set bit [i.e., the bit will remain 1]. Software shall clear this bit by writing a '1' to it. Refer to section 4.19.2 of xHCI specification for more information on change bit usage. (access R/W1TC)
  [16] LWS rw — Port Link State Write Strobe [LWS], RW. Default = '0'. When this bit is set to '1' on a write reference to this register, this flag enables writes to the PLS field. When '0', write data in PLS field is ignored. Reads to this bit return '0'.
  [15:14] PIC rw — Port Indicator Control [PIC], RWS. Default = '0'. Writing to these bits has no effect if the Port Indicators [PIND] bit in the HCCPARAMS register is a '0'. If PIND bit is a '1', then the bit encodings are: 0: Port indicators are off, 1: Amber, 2: Green, 3: Undefined. Refer to the USB2 Specification section 11.5.3 for a description on how these bits shall be used. This field is '0' if PP is '0'.
  [13:10] PORTSPEED ro — Port Speed [Port Speed], ROS. Default = '0'. This field identifies the speed of the connected USB Device. This field is only relevant if a device is connected [CCS = '1'] in all other cases this field shall indicate Undefined Speed. Possible values: 0: Undefined Speed 1-15: Protocol Speed ID [PSI], refer to section 7.2.1 of xHCI specification for the definition of PSIV field in the PSI Dword. Note: This field is invalid on a USB2 protocol port until after the port is reset.
  [9] PP rw — Port Power [PP], RWS. Default = '1'. This flag reflects a port's logical, power control state. Because host controllers can implement different methods of port power switching, this flag may or may not represent whether [VBus] power is actually applied to the port. When PP equals a '0' the port is nonfunctional and shall not report attaches, detaches, or Port Link State [PLS] changes. However, the port shall report over-current conditions when PP = '0' if PPC = '0'. After modifying PP, software shall read PP and confirm that it has reached its target state before modifying it again, undefined behavior may occur if this procedure is not followed. '0' = This port is in the Powered-off state. '1' = This port is not in the Powered-off state. If the Port Power Control [PPC] flag in the HCCPARAMS register is '1', then xHC has port power control switches and this bit represents the current setting of the switch ['0' = off, '1'=on]. If the Port Power Control [PPC] flag in the HCCPARAMS register is '0', then xHC does not have port power control switches and each port is hard wired to power, and not affected by this bit. When an over-current condition is detected on a powered port, the xHC shall transition the PP bit in each affected port from a '1' to '0' [removing power from the port]. Refer to section 4.19.4 for more information.
  [8:5] PLS rw — Port Link State [PLS], RWS. Default = RxDetect ['5']. This field is used to power manage the port and reflects its current link state. When the port is in the Enabled state, system software may set the link U state by writing this field. System software may also write this field to force a Disabled to Disconnected state transition of the port. Write Values: 0: The link shall transition to a U0 state from any of the U states. 2: The link should transition to the U2 State. 3: The link shall transition to a U3 state from the U0 state. This action selectively suspends the device connected to this port. While the Port Link State = U3, the hub does not propagate downstream-directed traffic to this port, but the hub shall respond to resume signaling from the port. 5: USB3 protocol ports only. If the port is in the Disabled state [PLS = Disabled, PP = 1], then the link shall transition to a RxDetect state and the port shall transition to the Disconnected state, else ignored. 10: USB3 protocol ports only. If CTC bit in HCCPARAMS2 is 2, it shall enable a link transition to the Compliance state, i.e. CTE = 1. Refer to section 4.19.1.2.4.1 of xHCI specification for more information. 15: If the port is in the U3 state [PLS = U3], then the link shall remain in the U3 state and the port shall transition to the Resume substate, else ignored. Refer to section 4.15.2 of xHCI specification for more information. others: Ignored. State Encoding: 0: Link is in the U0 State, 1: Link is in the U1 State, 2: Link is in the U2 State, 3: Link is in the U3 State [Device Suspended], 4: Link is in the Disabled State, 5: Link is in the RxDetect State, 6: Link is in the Inactive State, 7: Link is in the Polling State, 8: Link is in the Recovery State, 9: Link is in the Hot Reset State, 10 Link is in the Compliance Mode State, 11: Link is in the Test Mode State, 12-14: Reserved, 15: Link is in the Resume State. Note: The Port Link State Write Strobe [LWS] shall also be set to '1' to write this field. This field is undefined if PP = '0'. Writing a value of '2' to this field shall request LPM, asserting L1 signaling on the USB2 bus. Software may read this field to determine if the transition to the U2 state was successful. Writing a value of '0' shall deassert L1 signaling on the USB. Writing a value of '1' shall have no effect. The U1 state shall never be reported by a USB2 protocol port. Note: Transitions between different states are not reflected until the transition is complete. Refer to section 4.19 of xHCI specification for PLS transition conditions. Refer to sections 4.15.2 and 4.23.5 for more information on the use of this field. Refer to the USB2 LPM ECR for more information on USB link power management operation.
  [4] PR — Port Reset [PR], RW1S. Default = '0'. '1' = Port Reset signaling is asserted. '0' = Port is not in Reset. When software writes a '1' to this bit generating a '0' to '1' transition, the bus reset sequence is initiated. USB2 protocol ports shall execute the bus reset sequence as defined in the USB2 Spec. PR remains set until reset signaling is completed by the root hub. Note that software shall write a '1' to this flag to transition a USB2 port from the Polling state to the Enabled state. Refer to sections 4.15.2.3 and 4.19.1.1 of xHCI specification. This flag is '0' if PP is '0'. (access R/W1TS)
  [3] OCA ro — Over-current Active [OCA], RO. Default = '0'. '1' = This port currently has an over-current condition. '0' = This port does not have an over-current condition. This bit shall automatically transition from a '1' to a '0' when the over-current condition is removed.
  [1] PED — Port Enabled/Disabled [PED], RW1CS. Default = '0'. '1' = Enabled. '0' = Disabled. Ports may only be enabled by the xHC. Software cannot enable a port by writing a '1' to this flag. A port may be disabled by software writing a '1' to this flag. This flag shall automatically be cleared to '0' by a disconnect event or other fault condition. Note that the bit status does not change until the port state actually changes. There may be a delay in disabling or enabling a port due to other host controller or bus events. When the port is disabled [PED = '0'] downstream propagation of data is blocked on this port, except for reset. When the port is in the Disabled state, software shall reset the port [PR = '1'] to transition PED to '1' and the port to the Enabled state. Note that when software writes this bit to a '1', it shall also write a '0' to the PR bit. This flag is '0' if PP is '0'. (access R/W1TC)
  [0] CCS ro — Current Connect Status [CCS], ROS. Default = '0'. '1' = A device is connected to the port. '0' = A device is not connected. This value reflects the current state of the port, and may not correspond directly to the event that caused the Connect Status Change [CSC] bit to be set to '1'. Refer to sections 4.19.3 and 4.19.4 of xHCI specification for more details on the Connect Status Change [CSC] assertion conditions. This flag is '0' if PP is '0'.
